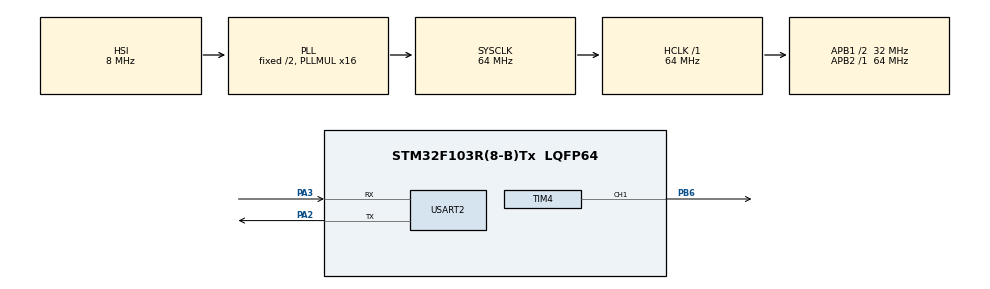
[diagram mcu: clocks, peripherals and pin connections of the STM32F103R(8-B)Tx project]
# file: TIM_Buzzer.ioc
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Mcu.Family=STM32F1
Mcu.Name=STM32F103R(8-B)Tx
Mcu.Package=LQFP64
NVIC.PriorityGroup=NVIC_PRIORITYGROUP_4
PA13.Mode=Serial_Wire
PA13.Signal=SYS_JTMS-SWDIO
PA14.Mode=Serial_Wire
PA14.Signal=SYS_JTCK-SWCLK
PA2.Mode=Asynchronous
PA2.Signal=USART2_TX
PA3.Mode=Asynchronous
PA3.Signal=USART2_RX
PB6.Signal=S_TIM4_CH1
ProjectManager.HeapSize=0x200
ProjectManager.StackSize=0x400
ProjectManager.TargetToolchain=STM32CubeIDE
RCC.AHBFreq_Value=64000000
RCC.APB1CLKDivider=RCC_HCLK_DIV2
RCC.APB1Freq_Value=32000000
RCC.APB1TimFreq_Value=64000000
RCC.APB2Freq_Value=64000000
RCC.APB2TimFreq_Value=64000000
RCC.HCLKFreq_Value=64000000
RCC.PLLMUL=RCC_PLL_MUL16
RCC.SYSCLKFreq_VALUE=64000000
RCC.SYSCLKSource=RCC_SYSCLKSOURCE_PLLCLK
RCC.USBFreq_Value=64000000
SH.S_TIM4_CH1.0=TIM4_CH1,PWM Generation1 CH1
TIM4.Channel-PWM\ Generation1\ CH1=TIM_CHANNEL_1
TIM4.Period=0
TIM4.Prescaler=63
TIM4.Pulse-PWM\ Generation1\ CH1=0
USART2.VirtualMode=VM_ASYNC
VP_TIM4_VS_ClockSourceINT.Mode=Internal
board=custom

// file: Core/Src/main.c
/* USER CODE BEGIN Header */
/**
  ******************************************************************************
  * @file           : main.c
  * @brief          : Main program body
  ******************************************************************************
  * @attention
  *
  * <h2><center>&copy; Copyright (c) 2020 STMicroelectronics.
  * All rights reserved.</center></h2>
  *
  * This software component is licensed by ST under BSD 3-Clause license,
  * the "License"; You may not use this file except in compliance with the
  * License. You may obtain a copy of the License at:
  *                        opensource.org/licenses/BSD-3-Clause
  *
  ******************************************************************************
  */
/* USER CODE END Header */

#include "main.h"

/* USER CODE BEGIN Includes */
#include <stdio.h>
/* USER CODE END Includes */

/* USER CODE BEGIN PM */
#define TIM4COUNTERCLOCK	1000000
/* USER CODE END PM */

TIM_HandleTypeDef htim4;

UART_HandleTypeDef huart2;

/* USER CODE BEGIN PV */
/* 소수점을 사용하지 않기 위해 100을 곱한 값 사용 */
enum notes
{
  C4 = 26163, // 도(261.63Hz)
  D4 = 29366, // 레(293.66Hz)
  E4 = 32963, // 미(329.63Hz)
  F4 = 34923, // 파(349.23Hz)
  G4 = 39200, // 솔(392.00Hz)
  A4 = 44000, // 라(440.00Hz)
  B4 = 49388, // 시(493.88Hz)
  C5 = 52325  // 도(523.25Hz)
};

/* 학교종
 * 솔 솔 라 라 솔 솔 미 솔 솔 미 미 레
 * 솔 솔 라 라 솔 솔 미 솔 미 레 미 도 */
enum notes SchoolBell[] = {G4, G4, A4, A4, G4, G4, E4, G4, G4, E4, E4, D4,
			  	  	  	  	  	  G4, G4, A4, A4, G4, G4, E4, G4, E4, D4, E4, C4};

/* USER CODE END PV */

void SystemClock_Config(void);
static void MX_GPIO_Init(void);
static void MX_TIM4_Init(void);
static void MX_USART2_UART_Init(void);

int main(void)
{

  /* MCU Configuration--------------------------------------------------------*/

  /* Reset of all peripherals, Initializes the Flash interface and the Systick. */
  HAL_Init();

  /* Configure the system clock */
  SystemClock_Config();

  /* Initialize all configured peripherals */
  MX_GPIO_Init();
  MX_TIM4_Init();
  MX_USART2_UART_Init();
  /* USER CODE BEGIN 2 */
  /* ### - 1 - Initialize TIM4 PWM (CubeMX ?��?�� ?��?��) ##################### */

  /* ### - 2 - Start PWM Signals generation for School Bell ############ */

  for (uint8_t i = 0; i < sizeof(SchoolBell) / sizeof(enum notes); i++)
    {
      /* Set the PWM Period */
      __HAL_TIM_SET_AUTORELOAD(&htim4, (int)(TIM4COUNTERCLOCK / SchoolBell[i] * 100));

      /* Set the PWM Pulse */
      __HAL_TIM_SET_COMPARE(&htim4, TIM_CHANNEL_1, TIM4COUNTERCLOCK / SchoolBell[i] * 100 / 2);
      HAL_TIM_PWM_Start (&htim4, TIM_CHANNEL_1);
      HAL_Delay (500);

      /* Interval between notes */
      HAL_TIM_PWM_Stop (&htim4, TIM_CHANNEL_1);
      HAL_Delay (10);
    }

  /* USER CODE END 2 */

  /* Infinite loop */
  while (1)
  {

  }
}

void SystemClock_Config(void)
{
  RCC_OscInitTypeDef RCC_OscInitStruct = {0};
  RCC_ClkInitTypeDef RCC_ClkInitStruct = {0};

  /** Initializes the CPU, AHB and APB busses clocks
  */
  RCC_OscInitStruct.OscillatorType = RCC_OSCILLATORTYPE_HSI;
  RCC_OscInitStruct.HSIState = RCC_HSI_ON;
  RCC_OscInitStruct.HSICalibrationValue = RCC_HSICALIBRATION_DEFAULT;
  RCC_OscInitStruct.PLL.PLLState = RCC_PLL_ON;
  RCC_OscInitStruct.PLL.PLLSource = RCC_PLLSOURCE_HSI_DIV2;
  RCC_OscInitStruct.PLL.PLLMUL = RCC_PLL_MUL16;
  if (HAL_RCC_OscConfig(&RCC_OscInitStruct) != HAL_OK)
  {
    Error_Handler();
  }
  /** Initializes the CPU, AHB and APB busses clocks
  */
  RCC_ClkInitStruct.ClockType = RCC_CLOCKTYPE_HCLK|RCC_CLOCKTYPE_SYSCLK
                              |RCC_CLOCKTYPE_PCLK1|RCC_CLOCKTYPE_PCLK2;
  RCC_ClkInitStruct.SYSCLKSource = RCC_SYSCLKSOURCE_PLLCLK;
  RCC_ClkInitStruct.AHBCLKDivider = RCC_SYSCLK_DIV1;
  RCC_ClkInitStruct.APB1CLKDivider = RCC_HCLK_DIV2;
  RCC_ClkInitStruct.APB2CLKDivider = RCC_HCLK_DIV1;

  if (HAL_RCC_ClockConfig(&RCC_ClkInitStruct, FLASH_LATENCY_2) != HAL_OK)
  {
    Error_Handler();
  }
}

static void MX_TIM4_Init(void)
{

  TIM_ClockConfigTypeDef sClockSourceConfig = {0};
  TIM_MasterConfigTypeDef sMasterConfig = {0};
  TIM_OC_InitTypeDef sConfigOC = {0};

  htim4.Instance = TIM4;
  htim4.Init.Prescaler = 63;
  htim4.Init.CounterMode = TIM_COUNTERMODE_UP;
  htim4.Init.Period = 0;
  htim4.Init.ClockDivision = TIM_CLOCKDIVISION_DIV1;
  htim4.Init.AutoReloadPreload = TIM_AUTORELOAD_PRELOAD_DISABLE;
  if (HAL_TIM_Base_Init(&htim4) != HAL_OK)
  {
    Error_Handler();
  }
  sClockSourceConfig.ClockSource = TIM_CLOCKSOURCE_INTERNAL;
  if (HAL_TIM_ConfigClockSource(&htim4, &sClockSourceConfig) != HAL_OK)
  {
    Error_Handler();
  }
  if (HAL_TIM_PWM_Init(&htim4) != HAL_OK)
  {
    Error_Handler();
  }
  sMasterConfig.MasterOutputTrigger = TIM_TRGO_RESET;
  sMasterConfig.MasterSlaveMode = TIM_MASTERSLAVEMODE_DISABLE;
  if (HAL_TIMEx_MasterConfigSynchronization(&htim4, &sMasterConfig) != HAL_OK)
  {
    Error_Handler();
  }
  sConfigOC.OCMode = TIM_OCMODE_PWM1;
  sConfigOC.Pulse = 0;
  sConfigOC.OCPolarity = TIM_OCPOLARITY_HIGH;
  sConfigOC.OCFastMode = TIM_OCFAST_DISABLE;
  if (HAL_TIM_PWM_ConfigChannel(&htim4, &sConfigOC, TIM_CHANNEL_1) != HAL_OK)
  {
    Error_Handler();
  }
  HAL_TIM_MspPostInit(&htim4);

}

static void MX_USART2_UART_Init(void)
{

  huart2.Instance = USART2;
  huart2.Init.BaudRate = 115200;
  huart2.Init.WordLength = UART_WORDLENGTH_8B;
  huart2.Init.StopBits = UART_STOPBITS_1;
  huart2.Init.Parity = UART_PARITY_NONE;
  huart2.Init.Mode = UART_MODE_TX_RX;
  huart2.Init.HwFlowCtl = UART_HWCONTROL_NONE;
  huart2.Init.OverSampling = UART_OVERSAMPLING_16;
  if (HAL_UART_Init(&huart2) != HAL_OK)
  {
    Error_Handler();
  }

}

static void MX_GPIO_Init(void)
{

  /* GPIO Ports Clock Enable */
  __HAL_RCC_GPIOA_CLK_ENABLE();
  __HAL_RCC_GPIOB_CLK_ENABLE();

}

void Error_Handler(void)
{
}

/************************ (C) COPYRIGHT STMicroelectronics *****END OF FILE****/
